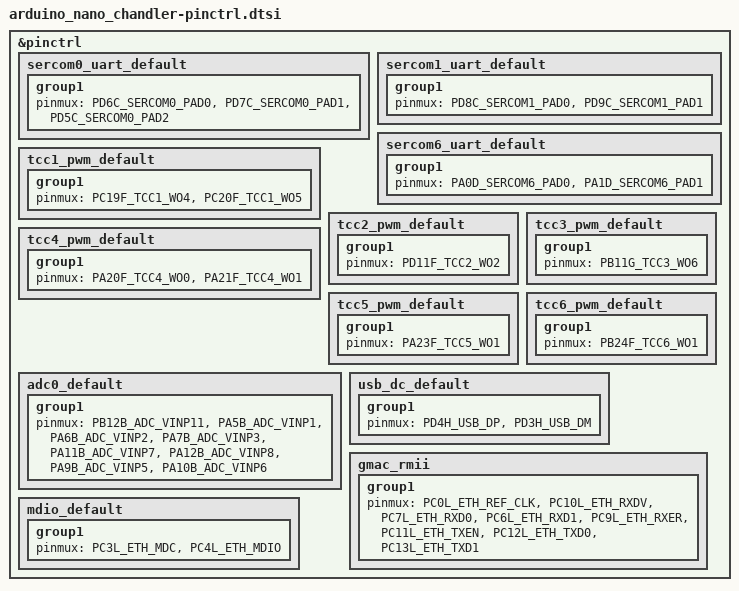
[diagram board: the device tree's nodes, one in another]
/*
 * Copyright (c) 2026 Arduino SA
 *
 * SPDX-License-Identifier: Apache-2.0
 */

#include <dt-bindings/pic32c/pic32ck_sg_gc/pic32ck_gc01/pic32ck2051gc01144-pinctrl.h>

&pinctrl {
	/* UART0 -> RS485 transceiver (THVD2410): TX/RX + RTS used as DE/RE */
	sercom0_uart_default: sercom0_uart_default {
		group1 {
			pinmux = <PD6C_SERCOM0_PAD0>,	/* TX  */
				 <PD7C_SERCOM0_PAD1>,	/* RX  */
				 <PD5C_SERCOM0_PAD2>;	/* RTS */
		};
	};

	/* UART1 -> user header (J3). Arduino `Serial`. */
	sercom1_uart_default: sercom1_uart_default {
		group1 {
			pinmux = <PD8C_SERCOM1_PAD0>,	/* TX */
				 <PD9C_SERCOM1_PAD1>;	/* RX */
		};
	};

	/* UART6 -> user header (J4). */
	sercom6_uart_default: sercom6_uart_default {
		group1 {
			pinmux = <PA0D_SERCOM6_PAD0>,	/* TX */
				 <PA1D_SERCOM6_PAD1>;	/* RX */
		};
	};

	/* TCC1 outputs used by D2/D3 */
	tcc1_pwm_default: tcc1_pwm_default {
		group1 {
			pinmux = /* <PC15F_TCC1_WO0>,
				 	<PC16F_TCC1_WO1>,
				 	<PC17F_TCC1_WO2>, */ 
					<PC19F_TCC1_WO4>,
				 	<PC20F_TCC1_WO5>;
		};
	};

	tcc2_pwm_default: tcc2_pwm_default {
		group1 {
			pinmux = <PD11F_TCC2_WO2>;
		};
	};

	tcc3_pwm_default: tcc3_pwm_default {
		group1 {
			pinmux = <PB11G_TCC3_WO6>;
		};
	};

	tcc4_pwm_default: tcc4_pwm_default {
		group1 {
			pinmux = <PA20F_TCC4_WO0>,
				 <PA21F_TCC4_WO1>;
		};
	};

	tcc5_pwm_default: tcc5_pwm_default {
		group1 {
			pinmux = <PA23F_TCC5_WO1>;
		};
	};

	tcc6_pwm_default: tcc6_pwm_default {
		group1 {
			pinmux = <PB24F_TCC6_WO1>;
		};
	};

	/* A0..A7 analog inputs: A0=PB12, A1=PA05, ..., A7=PA10. */
	adc0_default: adc0_default {
		group1 {
			pinmux = <PB12B_ADC_VINP11>,
				 <PA5B_ADC_VINP1>,
				 <PA6B_ADC_VINP2>,
				 <PA7B_ADC_VINP3>,
				 <PA11B_ADC_VINP7>,
				 <PA12B_ADC_VINP8>,
				 <PA9B_ADC_VINP5>,
				 <PA10B_ADC_VINP6>;
		};
	};

	/* USB FS device -> user header pins 2/4 (D+ = PD04, D- = PD03). */
	usb_dc_default: usb_dc_default {
		group1 {
			pinmux = <PD4H_USB_DP>,
				 <PD3H_USB_DM>;
		};
	};

	/* Ethernet RMII (mux L) -> KSZ8081 PHY. */
	gmac_rmii: gmac_rmii {
		group1 {
			pinmux = <PC0L_ETH_REF_CLK>,	/* 50 MHz RMII ref clock */
				 <PC10L_ETH_RXDV>,	/* CRS_DV */
				 <PC7L_ETH_RXD0>,
				 <PC6L_ETH_RXD1>,
				 <PC9L_ETH_RXER>,
				 <PC11L_ETH_TXEN>,
				 <PC12L_ETH_TXD0>,
				 <PC13L_ETH_TXD1>;
		};
	};

	/* Ethernet MDIO management bus (mux L). */
	mdio_default: mdio_default {
		group1 {
			pinmux = <PC3L_ETH_MDC>,
				 <PC4L_ETH_MDIO>;
		};
	};
};
